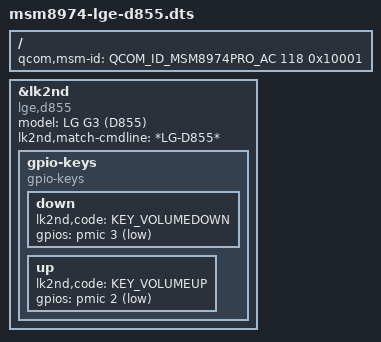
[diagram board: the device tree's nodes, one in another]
// SPDX-License-Identifier: BSD-3-Clause

#include <skeleton64.dtsi>
#include <lk2nd.dtsi>

/ {
	qcom,msm-id = <QCOM_ID_MSM8974PRO_AC 118 0x10001>;
};

&lk2nd {
	model = "LG G3 (D855)";
	compatible = "lge,d855";
	lk2nd,match-cmdline = "*LG-D855*";

	//FIXME: lk2nd,dtb-files = "msm8974-lge-d855";

	gpio-keys {
		compatible = "gpio-keys";
		down {
			lk2nd,code = <KEY_VOLUMEDOWN>;
			gpios = <&pmic 3 (GPIO_ACTIVE_LOW | GPIO_PULL_UP)>;
		};

		up {
			lk2nd,code = <KEY_VOLUMEUP>;
			gpios = <&pmic 2 (GPIO_ACTIVE_LOW | GPIO_PULL_UP)>;
		};
	};
};
